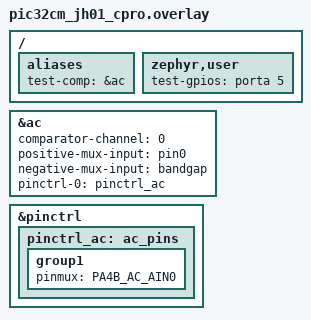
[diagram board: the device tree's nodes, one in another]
/*
 * Copyright (c) 2026 Microchip Technology Inc.
 *
 * SPDX-License-Identifier: Apache-2.0
 */

/* connect the PA04 to PA05 for the test */

/ {
	aliases {
		test-comp = &ac;
	};

	zephyr,user {
		test-gpios = <&porta 5 GPIO_ACTIVE_HIGH>;
	};
};

&ac {
	comparator-channel = <0>;
	positive-mux-input = "pin0";
	negative-mux-input = "bandgap";
	pinctrl-0 = <&pinctrl_ac>;
	pinctrl-names = "default";
	status = "okay";
};

&pinctrl {
	pinctrl_ac: ac_pins {
		group1 {
			pinmux = <PA4B_AC_AIN0>;
		};
	};
};
